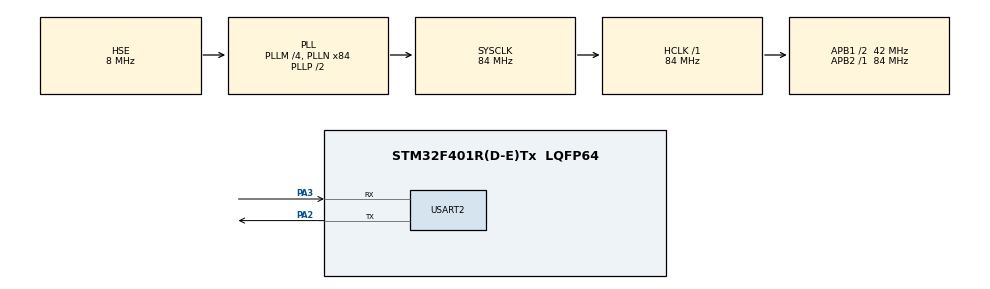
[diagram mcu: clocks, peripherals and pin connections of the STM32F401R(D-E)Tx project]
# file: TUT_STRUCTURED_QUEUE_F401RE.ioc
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FREERTOS.Tasks01=defaultTask,0,128,StartDefaultTask,Default,NULL,Dynamic,NULL,NULL
FREERTOS.configUSE_NEWLIB_REENTRANT=1
Mcu.Family=STM32F4
Mcu.Name=STM32F401R(D-E)Tx
Mcu.Package=LQFP64
NVIC.PriorityGroup=NVIC_PRIORITYGROUP_4
NVIC.TIM5_IRQn=true\:15\:0\:false\:false\:true\:false\:false\:true\:true
NVIC.TimeBase=TIM5_IRQn
NVIC.TimeBaseIP=TIM5
PA2.Mode=Asynchronous
PA2.Signal=USART2_TX
PA3.Mode=Asynchronous
PA3.Signal=USART2_RX
PH0\ -\ OSC_IN.Mode=HSE-External-Oscillator
PH0\ -\ OSC_IN.Signal=RCC_OSC_IN
PH1\ -\ OSC_OUT.Mode=HSE-External-Oscillator
PH1\ -\ OSC_OUT.Signal=RCC_OSC_OUT
ProjectManager.HeapSize=0x200
ProjectManager.StackSize=0x400
ProjectManager.TargetToolchain=STM32CubeIDE
RCC.48MHZClocksFreq_Value=42000000
RCC.AHBFreq_Value=84000000
RCC.APB1CLKDivider=RCC_HCLK_DIV2
RCC.APB1Freq_Value=42000000
RCC.APB1TimFreq_Value=84000000
RCC.APB2Freq_Value=84000000
RCC.APB2TimFreq_Value=84000000
RCC.CortexFreq_Value=84000000
RCC.HCLKFreq_Value=84000000
RCC.HSE_VALUE=8000000
RCC.HSI_VALUE=16000000
RCC.LSE_VALUE=32768
RCC.PLLM=4
RCC.PLLN=84
RCC.PLLSourceVirtual=RCC_PLLSOURCE_HSE
RCC.SYSCLKFreq_VALUE=84000000
RCC.SYSCLKSource=RCC_SYSCLKSOURCE_PLLCLK
RCC.VCOOutputFreq_Value=168000000
USART2.VirtualMode=VM_ASYNC
VP_FREERTOS_VS_CMSIS_V1.Mode=CMSIS_V1
VP_SYS_VS_tim5.Mode=TIM5
board=custom

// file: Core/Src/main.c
/* USER CODE BEGIN Header */
/**
  ******************************************************************************
  * @file           : main.c
  * @brief          : Main program body
  ******************************************************************************
  * @attention
  *
  * Copyright (c) 2025 STMicroelectronics.
  * All rights reserved.
  *
  * This software is licensed under terms that can be found in the LICENSE file
  * in the root directory of this software component.
  * If no LICENSE file comes with this software, it is provided AS-IS.
  *
  ******************************************************************************
  */
/* USER CODE END Header */
#include "main.h"
//#include "cmsis_os.h"

/* USER CODE BEGIN Includes */

#include "FreeRTOS.h"
#include "task.h"
#include "timers.h"
#include "queue.h"
#include "semphr.h"
#include "event_groups.h"

#include "string.h"
#include "stdio.h"

/* USER CODE END Includes */

UART_HandleTypeDef huart2;

void SystemClock_Config(void);
static void MX_GPIO_Init(void);
static void MX_USART2_UART_Init(void);

/* USER CODE BEGIN 0 */

/**************** QUEUE HANDLER ***********************/
xQueueHandle St_Queue_Handler;

/**************** TASK HANDLER ***********************/
xTaskHandle Sender1_Task_Handler;
xTaskHandle Sender2_Task_Handler;
xTaskHandle Receiver_Task_Handler;

/**************** TASK FUNCTIONS ***********************/
void Sender1_Task (void *argument);
void Sender2_Task (void *argument);
void Receiver_Task (void *argument);

/**************** STRUCTURE DEFINITION ***********************/

typedef struct {
	char *str;
	int counter;
	uint16_t large_value;
} my_struct;

int indx1 = 0;
int indx2 = 0;

/* USER CODE END 0 */

int main(void)
{

  /* MCU Configuration--------------------------------------------------------*/

  /* Reset of all peripherals, Initializes the Flash interface and the Systick. */
  HAL_Init();

  /* Configure the system clock */
  SystemClock_Config();

  /* Initialize all configured peripherals */
  MX_GPIO_Init();
  MX_USART2_UART_Init();
  /* USER CODE BEGIN 2 */

  /******** create QUEUE *********/
  St_Queue_Handler = xQueueCreate(2, sizeof (my_struct));

  if (St_Queue_Handler == 0)  // if there is some error while creating queue
  {
 	 char *str = "Unable to create STRUCTURE Queue\n\n";
 	 HAL_UART_Transmit(&huart2, (uint8_t *)str, strlen (str), HAL_MAX_DELAY);
  }
  else
  {
	 char *str = "STRUCTURE Queue Created successfully\n\n";
	 HAL_UART_Transmit(&huart2, (uint8_t *)str, strlen (str), HAL_MAX_DELAY);
  }

  /******** create QUEUE *********/
  xTaskCreate(Sender1_Task, "Sender1", 128, NULL, 2, &Sender1_Task_Handler);
  xTaskCreate(Sender2_Task, "Sender2", 128, NULL, 2, &Sender2_Task_Handler);
  xTaskCreate(Receiver_Task, "RECEIVER", 128, NULL, 1, &Receiver_Task_Handler);

  /******** start the scheduler *********/
  vTaskStartScheduler();

  /* USER CODE END 2 */

  /* We should never get here as control is now taken by the scheduler */

  /* Infinite loop */
  while (1)
  {

  }
}

void SystemClock_Config(void)
{
  RCC_OscInitTypeDef RCC_OscInitStruct = {0};
  RCC_ClkInitTypeDef RCC_ClkInitStruct = {0};

  /** Configure the main internal regulator output voltage
  */
  __HAL_RCC_PWR_CLK_ENABLE();
  __HAL_PWR_VOLTAGESCALING_CONFIG(PWR_REGULATOR_VOLTAGE_SCALE2);

  /** Initializes the RCC Oscillators according to the specified parameters
  * in the RCC_OscInitTypeDef structure.
  */
  RCC_OscInitStruct.OscillatorType = RCC_OSCILLATORTYPE_HSE;
  RCC_OscInitStruct.HSEState = RCC_HSE_ON;
  RCC_OscInitStruct.PLL.PLLState = RCC_PLL_ON;
  RCC_OscInitStruct.PLL.PLLSource = RCC_PLLSOURCE_HSE;
  RCC_OscInitStruct.PLL.PLLM = 4;
  RCC_OscInitStruct.PLL.PLLN = 84;
  RCC_OscInitStruct.PLL.PLLP = RCC_PLLP_DIV2;
  RCC_OscInitStruct.PLL.PLLQ = 4;
  if (HAL_RCC_OscConfig(&RCC_OscInitStruct) != HAL_OK)
  {
    Error_Handler();
  }

  /** Initializes the CPU, AHB and APB buses clocks
  */
  RCC_ClkInitStruct.ClockType = RCC_CLOCKTYPE_HCLK|RCC_CLOCKTYPE_SYSCLK
                              |RCC_CLOCKTYPE_PCLK1|RCC_CLOCKTYPE_PCLK2;
  RCC_ClkInitStruct.SYSCLKSource = RCC_SYSCLKSOURCE_PLLCLK;
  RCC_ClkInitStruct.AHBCLKDivider = RCC_SYSCLK_DIV1;
  RCC_ClkInitStruct.APB1CLKDivider = RCC_HCLK_DIV2;
  RCC_ClkInitStruct.APB2CLKDivider = RCC_HCLK_DIV1;

  if (HAL_RCC_ClockConfig(&RCC_ClkInitStruct, FLASH_LATENCY_2) != HAL_OK)
  {
    Error_Handler();
  }
}

static void MX_USART2_UART_Init(void)
{

  huart2.Instance = USART2;
  huart2.Init.BaudRate = 115200;
  huart2.Init.WordLength = UART_WORDLENGTH_8B;
  huart2.Init.StopBits = UART_STOPBITS_1;
  huart2.Init.Parity = UART_PARITY_NONE;
  huart2.Init.Mode = UART_MODE_TX_RX;
  huart2.Init.HwFlowCtl = UART_HWCONTROL_NONE;
  huart2.Init.OverSampling = UART_OVERSAMPLING_16;
  if (HAL_UART_Init(&huart2) != HAL_OK)
  {
    Error_Handler();
  }

}

static void MX_GPIO_Init(void)
{

  /* GPIO Ports Clock Enable */
  __HAL_RCC_GPIOH_CLK_ENABLE();
  __HAL_RCC_GPIOA_CLK_ENABLE();

}

/* USER CODE BEGIN 4 */

void Sender1_Task (void *argument)
{
	my_struct *ptrtostruct;

	uint32_t TickDelay = pdMS_TO_TICKS(2000);
	while (1)
	{
		char *str = "Entered SENDER1_Task\n about to SEND to the queue\n\n";
		HAL_UART_Transmit(&huart2, (uint8_t *)str, strlen (str), HAL_MAX_DELAY);

		/************ ALLOCATE MEMORY TO THE POINTER *****************/
		ptrtostruct = pvPortMalloc(sizeof (my_struct));

		/************ LOAD THE DATA ***********/
		ptrtostruct->counter = 1+indx1;
		ptrtostruct->large_value = 1000 + indx1*100;
		ptrtostruct->str = "HELLO FROM SENDER 1 ";

		/*********** send to the queue *******/
		if (xQueueSend(St_Queue_Handler, &ptrtostruct, portMAX_DELAY) == pdPASS)
		{
			char *str2 = "Successfully sent to the queue\nLeaving SENDER1Task\n\n\n";
			HAL_UART_Transmit(&huart2, (uint8_t *)str2, strlen (str2), HAL_MAX_DELAY);
		}

		indx1 = indx1+1;

		vTaskDelay(TickDelay);
	}

}

void Sender2_Task (void *argument)
{
	my_struct *ptrtostruct;

	uint32_t TickDelay = pdMS_TO_TICKS(2000);
	while (1)
	{
		char *str = "Entered SENDER2_Task\n about to SEND to the queue\n\n";
		HAL_UART_Transmit(&huart2, (uint8_t *)str, strlen (str), HAL_MAX_DELAY);

		/************ ALLOCATE MEMORY TO THE POINTER *****************/
		ptrtostruct = pvPortMalloc(sizeof (my_struct));

		/************ LOAD THE DATA ***********/
		ptrtostruct->str = "SENDER 2 says Hii!!!";
		ptrtostruct->large_value = 2000 + 200*indx2;
		ptrtostruct->counter = 1+indx1;

		/*********** send to the queue *******/
		if (xQueueSend(St_Queue_Handler, &ptrtostruct, portMAX_DELAY) == pdPASS)
		{
			char *str2 = "Successfully sent to the queue\nLeaving SENDER2Task\n\n\n";
			HAL_UART_Transmit(&huart2, (uint8_t *)str2, strlen (str2), HAL_MAX_DELAY);
		}

		indx2 = indx2+1;

		vTaskDelay(TickDelay);
	}

}

void Receiver_Task (void *argument)
{
	my_struct *Rptrtostruct;
	uint32_t TickDelay = pdMS_TO_TICKS(3000);
	char *ptr;

	while (1)
	{
		char *str = "Entrered RECEIVER Task\n about to RECEIVE FROM the queue\n\n";
		HAL_UART_Transmit(&huart2, (uint8_t *)str, strlen (str), HAL_MAX_DELAY);

		if (xQueueReceive(St_Queue_Handler, &Rptrtostruct, portMAX_DELAY) == pdPASS)
		{
			ptr = pvPortMalloc(100 * sizeof (char)); // allocae memory for the string

			sprintf (ptr, "Received from QUEUE:\n COUNTER = %d\n LARGE VALUE = %u\n STRING = %s\n\n\n",Rptrtostruct->counter,Rptrtostruct->large_value,Rptrtostruct->str);
			HAL_UART_Transmit(&huart2,  (uint8_t *)ptr, strlen (ptr), HAL_MAX_DELAY);

			vPortFree(ptr);
		}

		vPortFree(Rptrtostruct);

		vTaskDelay(TickDelay);
	}
}

/* USER CODE END 4 */

void HAL_TIM_PeriodElapsedCallback(TIM_HandleTypeDef *htim)
{
  if (htim->Instance == TIM5)
  {
    HAL_IncTick();
  }
}

void Error_Handler(void)
{
  __disable_irq();
  while (1)
  {
  }
}
